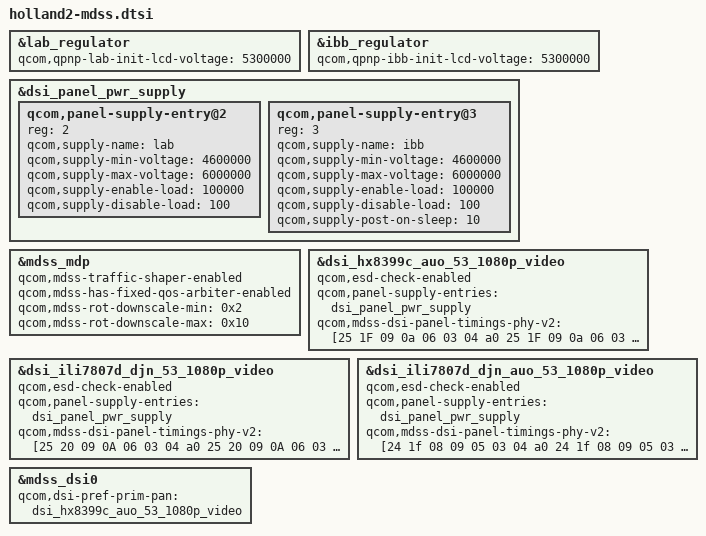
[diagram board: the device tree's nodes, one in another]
/* Copyright (c) 2020, The Linux Foundation. All rights reserved.
*  Copyright (c) 2020, Jebaitedneko.
*
* This program is free software; you can redistribute it and/or modify
* it under the terms of the GNU General Public License version 2 and
* only version 2 as published by the Free Software Foundation.
*
* This program is distributed in the hope that it will be useful,
* but WITHOUT ANY WARRANTY; without even the implied warranty of
* MERCHANTABILITY or FITNESS FOR A PARTICULAR PURPOSE.  See the
* GNU General Public License for more details.
*/

/delete-node/ &mdss_dsi1;

&lab_regulator {
	qcom,qpnp-lab-init-lcd-voltage = <5300000>;
};

&ibb_regulator {
	qcom,qpnp-ibb-init-lcd-voltage = <5300000>;
};

&dsi_panel_pwr_supply {

	qcom,panel-supply-entry@2 {

		reg = <2>;
		qcom,supply-name = "lab";
		qcom,supply-min-voltage = <4600000>;
		qcom,supply-max-voltage = <6000000>;
		qcom,supply-enable-load = <100000>;
		qcom,supply-disable-load = <100>;
	};

	qcom,panel-supply-entry@3 {

		reg = <3>;
		qcom,supply-name = "ibb";
		qcom,supply-min-voltage = <4600000>;
		qcom,supply-max-voltage = <6000000>;
		qcom,supply-enable-load = <100000>;
		qcom,supply-disable-load = <100>;
		qcom,supply-post-on-sleep = <10>;
	};
};

&mdss_mdp {

	qcom,mdss-traffic-shaper-enabled;
	qcom,mdss-has-fixed-qos-arbiter-enabled;
	qcom,mdss-rot-downscale-min = <0x2>;
	qcom,mdss-rot-downscale-max = <0x10>;
};

#include "dsi-panel-hx8399c-auo-53-1080p-video.dtsi"
#include "dsi-panel-ili7807d-djn-53-1080p-video.dtsi"
#include "dsi-panel-ili7807d-djn-auo-53-1080p-video.dtsi"

&dsi_hx8399c_auo_53_1080p_video {

	qcom,esd-check-enabled;
	qcom,panel-supply-entries = <&dsi_panel_pwr_supply>;

	qcom,mdss-dsi-panel-timings-phy-v2  = [25 1F 09 0a 06 03 04 a0
		25 1F 09 0a 06 03 04 a0
		25 1F 09 0a 06 03 04 a0
		25 1F 09 0a 06 03 04 a0
	        25 1E 08 0a 06 03 04 a0];
};

&dsi_ili7807d_djn_53_1080p_video {

	qcom,esd-check-enabled;
	qcom,panel-supply-entries = <&dsi_panel_pwr_supply>;

	qcom,mdss-dsi-panel-timings-phy-v2  = [25 20 09 0A 06 03 04 a0
		25 20 09 0A 06 03 04 a0
		25 20 09 0A 06 03 04 a0
		25 20 09 0A 06 03 04 a0
	        25 1E 09 0A 06 03 04 a0];
};

&dsi_ili7807d_djn_auo_53_1080p_video {

	qcom,esd-check-enabled;
	qcom,panel-supply-entries = <&dsi_panel_pwr_supply>;

	qcom,mdss-dsi-panel-timings-phy-v2  = [24 1f 08 09 05 03 04 a0
		24 1f 08 09 05 03 04 a0
		24 1f 08 09 05 03 04 a0
		24 1f 08 09 05 03 04 a0
	        24 1b 08 08 05 03 04 a0];
};

&mdss_dsi0 {
	qcom,dsi-pref-prim-pan = <&dsi_hx8399c_auo_53_1080p_video>;
};

/delete-node/ &dsi_adv7533_1080p;
/delete-node/ &dsi_boent51021_1200p_video;
/delete-node/ &dsi_boyi_hx83100a_800p_video;
/delete-node/ &dsi_dual_sim_cmd;
/delete-node/ &dsi_dual_sim_vid;
/delete-node/ &dsi_hx8394d_kingdisplay_vid;
/delete-node/ &dsi_hx8399c_truly_vid;
/delete-node/ &dsi_lt8912_1080_vid;
/delete-node/ &dsi_lt8912_480_vid;
/delete-node/ &dsi_r69006_1080p_cmd;
/delete-node/ &dsi_r69006_1080p_video;
/delete-node/ &dsi_sim_cmd;
/delete-node/ &dsi_sim_vid;
/delete-node/ &dsi_truly_1080_cmd;
/delete-node/ &dsi_truly_1080_vid;
/delete-node/ &dsi_truly_wuxga_vid;
/delete-node/ &dsi_inxnt51021_1200p_video;
/delete-node/ &dsi_adv7533_720p;
